# sfe_reva_es17 register map
Registers are access not given, no defined reset value unless marked. A register's access mark holds for its fields unless they carry their own. Offsets are from the block's base; lines under a group give offsets from that group; [hi:lo] are bit positions; {n}, {i} and the like mark numbered series; 'fields as' and 'values as' point back to an identical list; <NAME> marks a mode.

## Memory map
0x400A0000 SFE size 0x1000 — Serial Flash Emulator.

## SFE — Serial Flash Emulator.
Base 0x400A0000
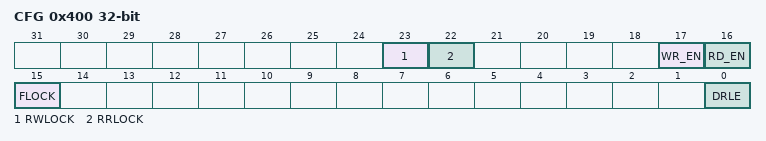
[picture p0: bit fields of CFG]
0x400 CFG 32-bit — SFE Configuration Register.
  [23] RWLOCK — RAM Write Lock.
  [22] RRLOCK — RAM Read Lock.
  [17] WR_EN — RAM Write Enable.
  [16] RD_EN — RAM Read Enable.
  [15] FLOCK — Flash Lock.
  [0] DRLE — Data Rise Launch Edge Enable.
0x408 HFSA — SFE Host Flash Start Address Register.
  [31:10] HFSA — Serial Flash Host Flash Start Address.
0x40C HRSA — SFE Host RAM Start Address Register.
  [31:10] HRSA — Serial Flash Host RAM Start Address.
0x410 SFDP_SBA — SFE Discoverable Parameter System Base Register.
  [31:8] SFDP_SBA — SFDP upper 24 bits System Base Address.
0x414 FLASH_SBA — Flash System Base Address Register.
  [31:10] FLASH_SBA — FLASH upper 22 bits System Base Address.
0x418 FLASH_STA — Flash System Top Address Register.
  [31:10] FLASH_STA — FLASH upper 22 bits System Top Address.
0x41C RAM_SBA — RAM System Base Address Register.
  [31:10] RAM_SBA — RAM upper 22 bits System Base Address.
0x420 RAM_STA — RAM System Top Address Register.
  [31:10] RAM_STA — RAM upper 22 bits System Top Address.
